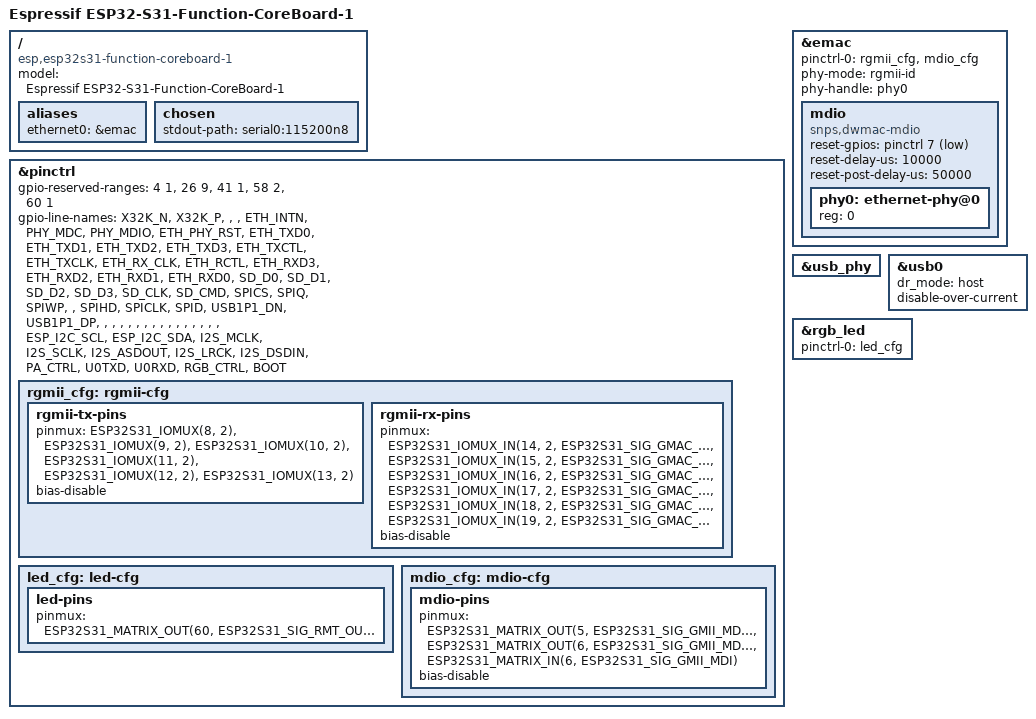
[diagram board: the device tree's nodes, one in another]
// SPDX-License-Identifier: GPL-2.0+
/*
 * ESP32-S31-Function-CoreBoard-1, with the ESP32-S31-WROOM-3-N16R16V module:
 * UART0 on the USB-UART bridge, Gigabit Ethernet, a USB 2.0 host port and a
 * WS2812 RGB LED.
 * The root is on a USB stick.
 * Author: Roan Brand <brandroan@gmail.com>
 */
/dts-v1/;
#include "esp32s31.dtsi"
#include <dt-bindings/gpio/gpio.h>

/ {
	model = "Espressif ESP32-S31-Function-CoreBoard-1";
	compatible = "esp,esp32s31-function-coreboard-1", "esp,esp32s31";

	aliases {
		ethernet0 = &emac;
	};

	chosen {
		stdout-path = "serial0:115200n8";
	};
};

&pinctrl {
	/* The SoC list, ETH_INTN of the PHY (GPIO4, on J2), the LED (GPIO60). */
	gpio-reserved-ranges = <4 1>, <26 9>, <41 1>, <58 2>, <60 1>;
	/* The nets of the board; the flash pins of the module. */
	gpio-line-names =
		/*  0 */ "X32K_N", "X32K_P", "", "", "ETH_INTN", "PHY_MDC",
		/*  6 */ "PHY_MDIO", "ETH_PHY_RST", "ETH_TXD0", "ETH_TXD1",
		/* 10 */ "ETH_TXD2", "ETH_TXD3", "ETH_TXCTL", "ETH_TXCLK",
		/* 14 */ "ETH_RX_CLK", "ETH_RCTL", "ETH_RXD3", "ETH_RXD2",
		/* 18 */ "ETH_RXD1", "ETH_RXD0", "SD_D0", "SD_D1", "SD_D2",
		/* 23 */ "SD_D3", "SD_CLK", "SD_CMD", "SPICS", "SPIQ",
		/* 28 */ "SPIWP", "", "SPIHD", "SPICLK", "SPID", "USB1P1_DN",
		/* 34 */ "USB1P1_DP", "", "", "", "", "", "", "", "", "", "",
		/* 45 */ "", "", "", "", "", "ESP_I2C_SCL", "ESP_I2C_SDA",
		/* 52 */ "I2S_MCLK", "I2S_SCLK", "I2S_ASDOUT", "I2S_LRCK",
		/* 56 */ "I2S_DSDIN", "PA_CTRL", "U0TXD", "U0RXD", "RGB_CTRL",
		/* 61 */ "BOOT";

	/* The RGMII pins of the IO MUX, function 2 */
	rgmii_cfg: rgmii-cfg {
		rgmii-tx-pins {
			pinmux = <ESP32S31_IOMUX(8, 2)>,	/* TXD0 */
				 <ESP32S31_IOMUX(9, 2)>,	/* TXD1 */
				 <ESP32S31_IOMUX(10, 2)>,	/* TXD2 */
				 <ESP32S31_IOMUX(11, 2)>,	/* TXD3 */
				 <ESP32S31_IOMUX(12, 2)>,	/* TX_CTL */
				 <ESP32S31_IOMUX(13, 2)>;	/* TX_CLK */
			bias-disable;
		};

		rgmii-rx-pins {
			pinmux = <ESP32S31_IOMUX_IN(14, 2, ESP32S31_SIG_GMAC_RX_CLK)>,
				 <ESP32S31_IOMUX_IN(15, 2, ESP32S31_SIG_GMAC_RXDV)>,
				 <ESP32S31_IOMUX_IN(16, 2, ESP32S31_SIG_GMAC_RXD3)>,
				 <ESP32S31_IOMUX_IN(17, 2, ESP32S31_SIG_GMAC_RXD2)>,
				 <ESP32S31_IOMUX_IN(18, 2, ESP32S31_SIG_GMAC_RXD1)>,
				 <ESP32S31_IOMUX_IN(19, 2, ESP32S31_SIG_GMAC_RXD0)>;
			bias-disable;
		};
	};

	led_cfg: led-cfg {
		led-pins {
			pinmux = <ESP32S31_MATRIX_OUT(60, ESP32S31_SIG_RMT_OUT0)>;
		};
	};

	mdio_cfg: mdio-cfg {
		mdio-pins {
			pinmux = <ESP32S31_MATRIX_OUT(5, ESP32S31_SIG_GMII_MDC)>,
				 <ESP32S31_MATRIX_OUT(6, ESP32S31_SIG_GMII_MDO)>,
				 <ESP32S31_MATRIX_IN(6, ESP32S31_SIG_GMII_MDI)>;
			bias-disable;
		};
	};
};

/* YT8531 PHY: after a chip reset it passes no frames, so MDIO resets it. */
&emac {
	pinctrl-names = "default";
	pinctrl-0 = <&rgmii_cfg>, <&mdio_cfg>;
	phy-mode = "rgmii-id";
	phy-handle = <&phy0>;
	status = "okay";

	mdio {
		compatible = "snps,dwmac-mdio";
		#address-cells = <1>;
		#size-cells = <0>;
		reset-gpios = <&pinctrl 7 GPIO_ACTIVE_LOW>;
		reset-delay-us = <10000>;
		reset-post-delay-us = <50000>;

		phy0: ethernet-phy@0 {
			reg = <0>;
		};
	};
};

/* The Type-A port: host only, with a TPS2051C switch for VBUS. */
&usb_phy { status = "okay"; };

&usb0 {
	dr_mode = "host";
	disable-over-current;
	status = "okay";
};

/* WS2812 RGB LED on GPIO60. */
&rgb_led {
	pinctrl-names = "default";
	pinctrl-0 = <&led_cfg>;
	status = "okay";
};
